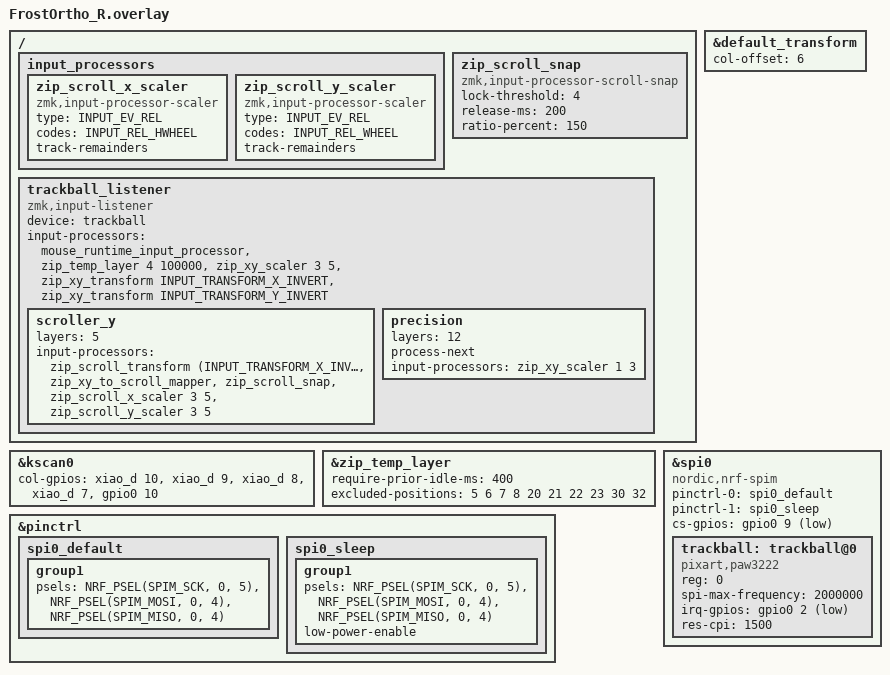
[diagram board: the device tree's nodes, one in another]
#include "FrostOrtho.dtsi"
#include <input/processors.dtsi>
#include <dt-bindings/zmk/input_transform.h>
#include <zephyr/dt-bindings/input/input-event-codes.h>
#include <input/processors/runtime-input-processor.dtsi>
#include <behaviors/battery_history_request.dtsi>

&default_transform {
    col-offset = <6>;
};

&kscan0 {
    col-gpios
        = <&xiao_d 10 GPIO_ACTIVE_HIGH>
        , <&xiao_d 9 GPIO_ACTIVE_HIGH> 
        , <&xiao_d 8 GPIO_ACTIVE_HIGH> 
        , <&xiao_d 7 GPIO_ACTIVE_HIGH> 
        , <&gpio0 10 GPIO_ACTIVE_HIGH>
        ;
};

&zip_temp_layer {
    // キー入力後400ms以内はAMLに切り替わらない
    require-prior-idle-ms = <400>;
    // AMLから離脱しないキー
    excluded-positions = <
        5 // Y 左クリック
        6 // U スクロール(L5)
        7 // I 右クリック
        8 // O ドラッグ固定
        20 // Z 取り消し / Shift
        21 // X 切り取り
        22 // C コピー
        23 // V 貼り付け
        30 // Del / Cmd
        32 // Alt
    >;
};

/ {
    input_processors {
        zip_scroll_x_scaler: zip_scroll_x_scaler {
            compatible = "zmk,input-processor-scaler";
            #input-processor-cells = <2>;
            type = <INPUT_EV_REL>;
            codes = <INPUT_REL_HWHEEL>;
            track-remainders;
        };
        zip_scroll_y_scaler: zip_scroll_y_scaler {
            compatible = "zmk,input-processor-scaler";
            #input-processor-cells = <2>;
            type = <INPUT_EV_REL>;
            codes = <INPUT_REL_WHEEL>;
            track-remainders;
        };
    };
};

/ {
    zip_scroll_snap: zip_scroll_snap {
        compatible = "zmk,input-processor-scroll-snap";
        #input-processor-cells = <0>;
        lock-threshold = <4>; // 向きを決めるまでの移動量
        release-ms = <200>;   // 止めてからこの時間で固定解除
        ratio-percent = <150>; // 横が縦の1.5倍を超えたら横スクロール
    };
};

/ {
    trackball_listener: trackball_listener {
        status = "okay";
        compatible = "zmk,input-listener";
        device = <&trackball>;

        // input-processors = <&mouse_runtime_input_processor>;
        input-processors = <
            &mouse_runtime_input_processor
            &zip_temp_layer 4 100000 // AMLレイヤー(4)、タイムアウト時間
            &zip_xy_scaler 3 5 // カーソル移動量3/5倍(2/3から少し遅く)
            &zip_xy_transform INPUT_TRANSFORM_X_INVERT // カーソルの移動方向調整
            &zip_xy_transform INPUT_TRANSFORM_Y_INVERT // カーソルの移動方向調整
        >;
    };
};

&trackball_listener {
    scroller_y {
        layers = <5>; // 縦スクロールレイヤー
        input-processors = <
            // &scroll_runtime_input_processor
            &zip_scroll_transform (INPUT_TRANSFORM_X_INVERT) // スクロール方向調整
            &zip_xy_to_scroll_mapper
            &zip_scroll_snap // 縦か横のどちらか一方に固定(動かし始めの向き)
            &zip_scroll_x_scaler 3 5 // X軸(横)スクロール量3/5倍 ボールを横に転がすと横スクロール
            &zip_scroll_y_scaler 3 5 // Y軸スクロール量3/5倍(2/3から少し遅く)
        >;
    };
    // 精密モード(レイヤー12): カーソル移動量を1/3に。process-nextで通常の処理も続けて通す
    precision {
        layers = <12>;
        process-next;
        input-processors = <&zip_xy_scaler 1 3>;
    };
};

&pinctrl {
    spi0_default: spi0_default {
        group1 {
            psels = <NRF_PSEL(SPIM_SCK, 0, 5)>,
                <NRF_PSEL(SPIM_MOSI, 0, 4)>,
                <NRF_PSEL(SPIM_MISO, 0, 4)>;
        };
    };

    spi0_sleep: spi0_sleep {
        group1 {
            psels = <NRF_PSEL(SPIM_SCK, 0, 5)>,
                <NRF_PSEL(SPIM_MOSI, 0, 4)>,
                <NRF_PSEL(SPIM_MISO, 0, 4)>;
            low-power-enable;
        };
    };
};

&spi0 {
    status = "okay";
    compatible = "nordic,nrf-spim";
    pinctrl-0 = <&spi0_default>;
    pinctrl-1 = <&spi0_sleep>;
    pinctrl-names = "default", "sleep";
    cs-gpios = <&gpio0 9 GPIO_ACTIVE_LOW>;

    trackball: trackball@0 {
        status = "okay";
        compatible = "pixart,paw3222";
        reg = <0>;
        spi-max-frequency = <2000000>;
        irq-gpios = <&gpio0 2 (GPIO_ACTIVE_LOW | GPIO_PULL_UP)>;
        res-cpi = <1500>;
    };
};


